# STM32F303xE register map
File version: 1.0
Registers are 32-bit, read-write, reset 0x0 unless marked. A register's access mark holds for its fields unless they carry their own. Offsets are from the block's base; [hi:lo] are bit positions; {n}, {i} and the like mark numbered series.

## WWDG — Window WATCHDOG
Base 0x40002C00
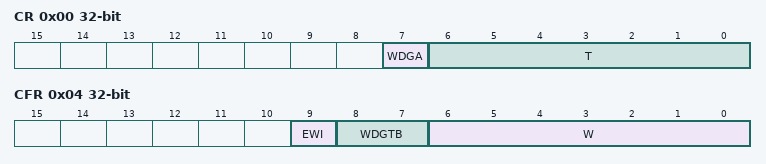
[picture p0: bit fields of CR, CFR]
0x00 CR — WWDG Control register
  [7] WDGA — Activation bit
  [6:0] T — T[6:0] bits (7-Bit counter (MSB to LSB))
0x04 CFR — WWDG Configuration register
  [9] EWI — Early Wakeup Interrupt
  [8:7] WDGTB — WDGTB[1:0] bits (Timer Base)
    0=PRESCALER_1 (WWDG counter clock = (PCLK1/4096)/1); 1=PRESCALER_2 (WWDG counter clock = (PCLK1/4096)/2); 2=PRESCALER_4 (WWDG counter clock = (PCLK1/4096)/4); 3=PRESCALER_8 (WWDG counter clock = (PCLK1/4096)/8)
  [6:0] W — W[6:0] bits (7-bit window value)
0x08 SR — WWDG Status register
  [0] EWIF — Early Wakeup Interrupt Flag

## IWDG — Independent WATCHDOG
Base 0x40003000
0x00 KR — IWDG Key register
  [15:0] KEY — Key value (write only, read 0000h)
0x04 PR — IWDG Prescaler register
  [2:0] PR — PR[2:0] (Prescaler divider)
0x08 RLR — IWDG Reload register
  [11:0] RL — Watchdog counter reload value
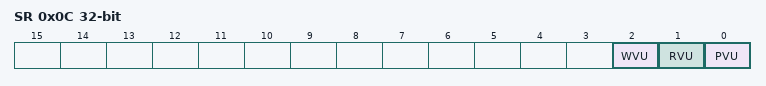
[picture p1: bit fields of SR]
0x0C SR — IWDG Status register
  [2] WVU — Watchdog counter window value update
  [1] RVU — Watchdog counter reload value update
  [0] PVU — Watchdog prescaler value update
0x10 WINR — IWDG Window register
  [11:0] WIN — Watchdog counter window value

## USB — Universal Serial Bus Full Speed Device
Base 0x40005C00
{0x0+4i} EP{i}R 16-bit (i=0..7) — USB Endpoint {i} register
0x40 CNTR 16-bit — Control register
0x44 ISTR 16-bit — Interrupt status register
0x48 FNR 16-bit — Frame number register
0x4C DADDR 16-bit — Device address register
0x50 BTABLE 16-bit — Buffer Table address register
0x54 LPMCSR 16-bit — LPM Control and Status register

## PWR — Power Control
Base 0x40007000
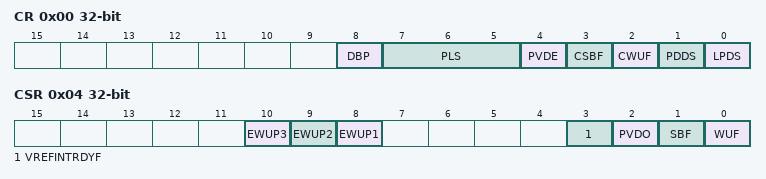
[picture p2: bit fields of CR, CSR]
0x00 CR — PWR power control register
  [8] DBP — Disable Backup Domain write protection
  [7:5] PLS — PLS[2:0] bits (PVD Level Selection)
    0=PVDLEVEL_0 (Voltage threshold detected by PVD 2.2 V); 1=PVDLEVEL_1 (Voltage threshold detected by PVD 2.3 V); 2=PVDLEVEL_2 (Voltage threshold detected by PVD 2.4 V); 3=PVDLEVEL_3 (Voltage threshold detected by PVD 2.5 V); 4=PVDLEVEL_4 (Voltage threshold detected by PVD 2.6 V); 5=PVDLEVEL_5 (Voltage threshold detected by PVD 2.7 V); 6=PVDLEVEL_6 (Voltage threshold detected by PVD 2.8 V); 7=PVDLEVEL_7 (Voltage threshold detected by PVD 2.9 V)
  [4] PVDE — Power Voltage Detector Enable
  [3] CSBF — Clear Standby Flag
  [2] CWUF — Clear Wakeup Flag
  [1] PDDS — Power Down Deepsleep
  [0] LPDS — Low-power Deepsleep
    0=MAIN (Voltage Regulator in main mode during deepsleep mode); 1=LOW_POWER (Voltage Regulator in low-power mode during deepsleep mode)
0x04 CSR — PWR power control/status register
  [10] EWUP3 — Enable WKUP pin 3
  [9] EWUP2 — Enable WKUP pin 2
  [8] EWUP1 — Enable WKUP pin 1
  [3] VREFINTRDYF — Internal voltage reference (VREFINT) ready flag
  [2] PVDO — PVD Output
  [1] SBF — Standby Flag
  [0] WUF — Wakeup Flag

## DAC — Digital to Analog Converter
Base 0x40007400
Same registers: DAC1 0x40007400 (alternate view of DAC)
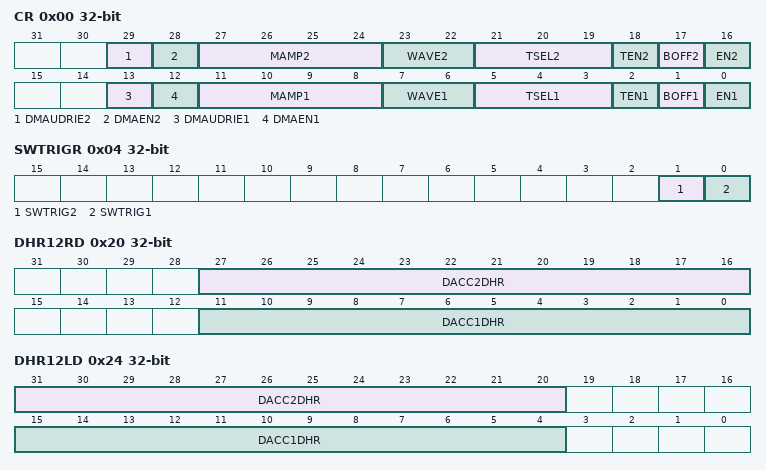
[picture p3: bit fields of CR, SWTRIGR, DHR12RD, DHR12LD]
0x00 CR — DAC control register
  [29] DMAUDRIE2 — DAC channel2 DMA underrun IT enable
  [28] DMAEN2 — DAC channel2 DMA enabled
  [27:24] MAMP2 — MAMP2[3:0] (DAC channel2 Mask/Amplitude selector)
  [23:22] WAVE2 — WAVE2[1:0] (DAC channel2 noise/triangle wave generation enable)
  [21:19] TSEL2 — TSEL2[2:0] (DAC channel2 Trigger selection)
  [18] TEN2 — DAC channel2 Trigger enable
  [17] BOFF2 — DAC channel2 output buffer disable
  [16] EN2 — DAC channel2 enable
  [13] DMAUDRIE1 — DAC channel1 DMA underrun IT enable
  [12] DMAEN1 — DAC channel1 DMA enable
  [11:8] MAMP1 — MAMP1[3:0] (DAC channel1 Mask/Amplitude selector)
  [7:6] WAVE1 — WAVE1[1:0] (DAC channel1 noise/triangle wave generation enable)
  [5:3] TSEL1 — TSEL1[2:0] (DAC channel1 Trigger selection)
  [2] TEN1 — DAC channel1 Trigger enable
  [1] BOFF1 — DAC channel1 output buffer disable
  [0] EN1 — DAC channel1 enable
0x04 SWTRIGR — DAC software trigger register
  [1] SWTRIG2 — DAC channel2 software trigger
  [0] SWTRIG1 — DAC channel1 software trigger
0x08 DHR12R1 — DAC channel1 12-bit right-aligned data holding register
  [11:0] DACC1DHR — DAC channel1 12-bit Right aligned data
0x0C DHR12L1 — DAC channel1 12-bit left aligned data holding register
  [15:4] DACC1DHR — DAC channel1 12-bit Left aligned data
0x10 DHR8R1 — DAC channel1 8-bit right aligned data holding register
  [7:0] DACC1DHR — DAC channel1 8-bit Right aligned data
0x14 DHR12R2 — DAC channel2 12-bit right aligned data holding register
  [11:0] DACC2DHR — DAC channel2 12-bit Right aligned data
0x18 DHR12L2 — DAC channel2 12-bit left aligned data holding register
  [15:4] DACC2DHR — DAC channel2 12-bit Left aligned data
0x1C DHR8R2 — DAC channel2 8-bit right-aligned data holding register
  [7:0] DACC2DHR — DAC channel2 8-bit Right aligned data
0x20 DHR12RD — Dual DAC 12-bit right-aligned data holding register
  [27:16] DACC2DHR — DAC channel2 12-bit Right aligned data
  [11:0] DACC1DHR — DAC channel1 12-bit Right aligned data
0x24 DHR12LD — DUAL DAC 12-bit left aligned data holding register
  [31:20] DACC2DHR — DAC channel2 12-bit Left aligned data
  [15:4] DACC1DHR — DAC channel1 12-bit Left aligned data
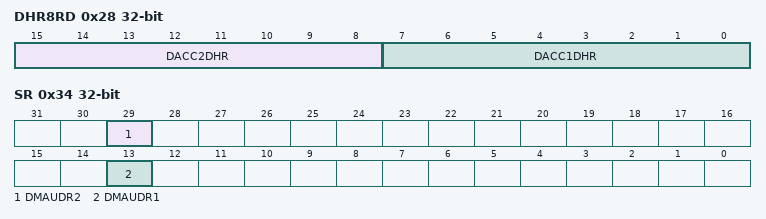
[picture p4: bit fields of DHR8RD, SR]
0x28 DHR8RD — DUAL DAC 8-bit right aligned data holding register
  [15:8] DACC2DHR — DAC channel2 8-bit Right aligned data
  [7:0] DACC1DHR — DAC channel1 8-bit Right aligned data
0x2C DOR1 — DAC channel1 data output register
  [11:0] DACC1DOR — DAC channel1 data output
0x30 DOR2 — DAC channel2 data output register
  [11:0] DACC2DOR — DAC channel2 data output
0x34 SR — DAC status register
  [29] DMAUDR2 — DAC channel2 DMA underrun flag
  [13] DMAUDR1 — DAC channel1 DMA underrun flag
